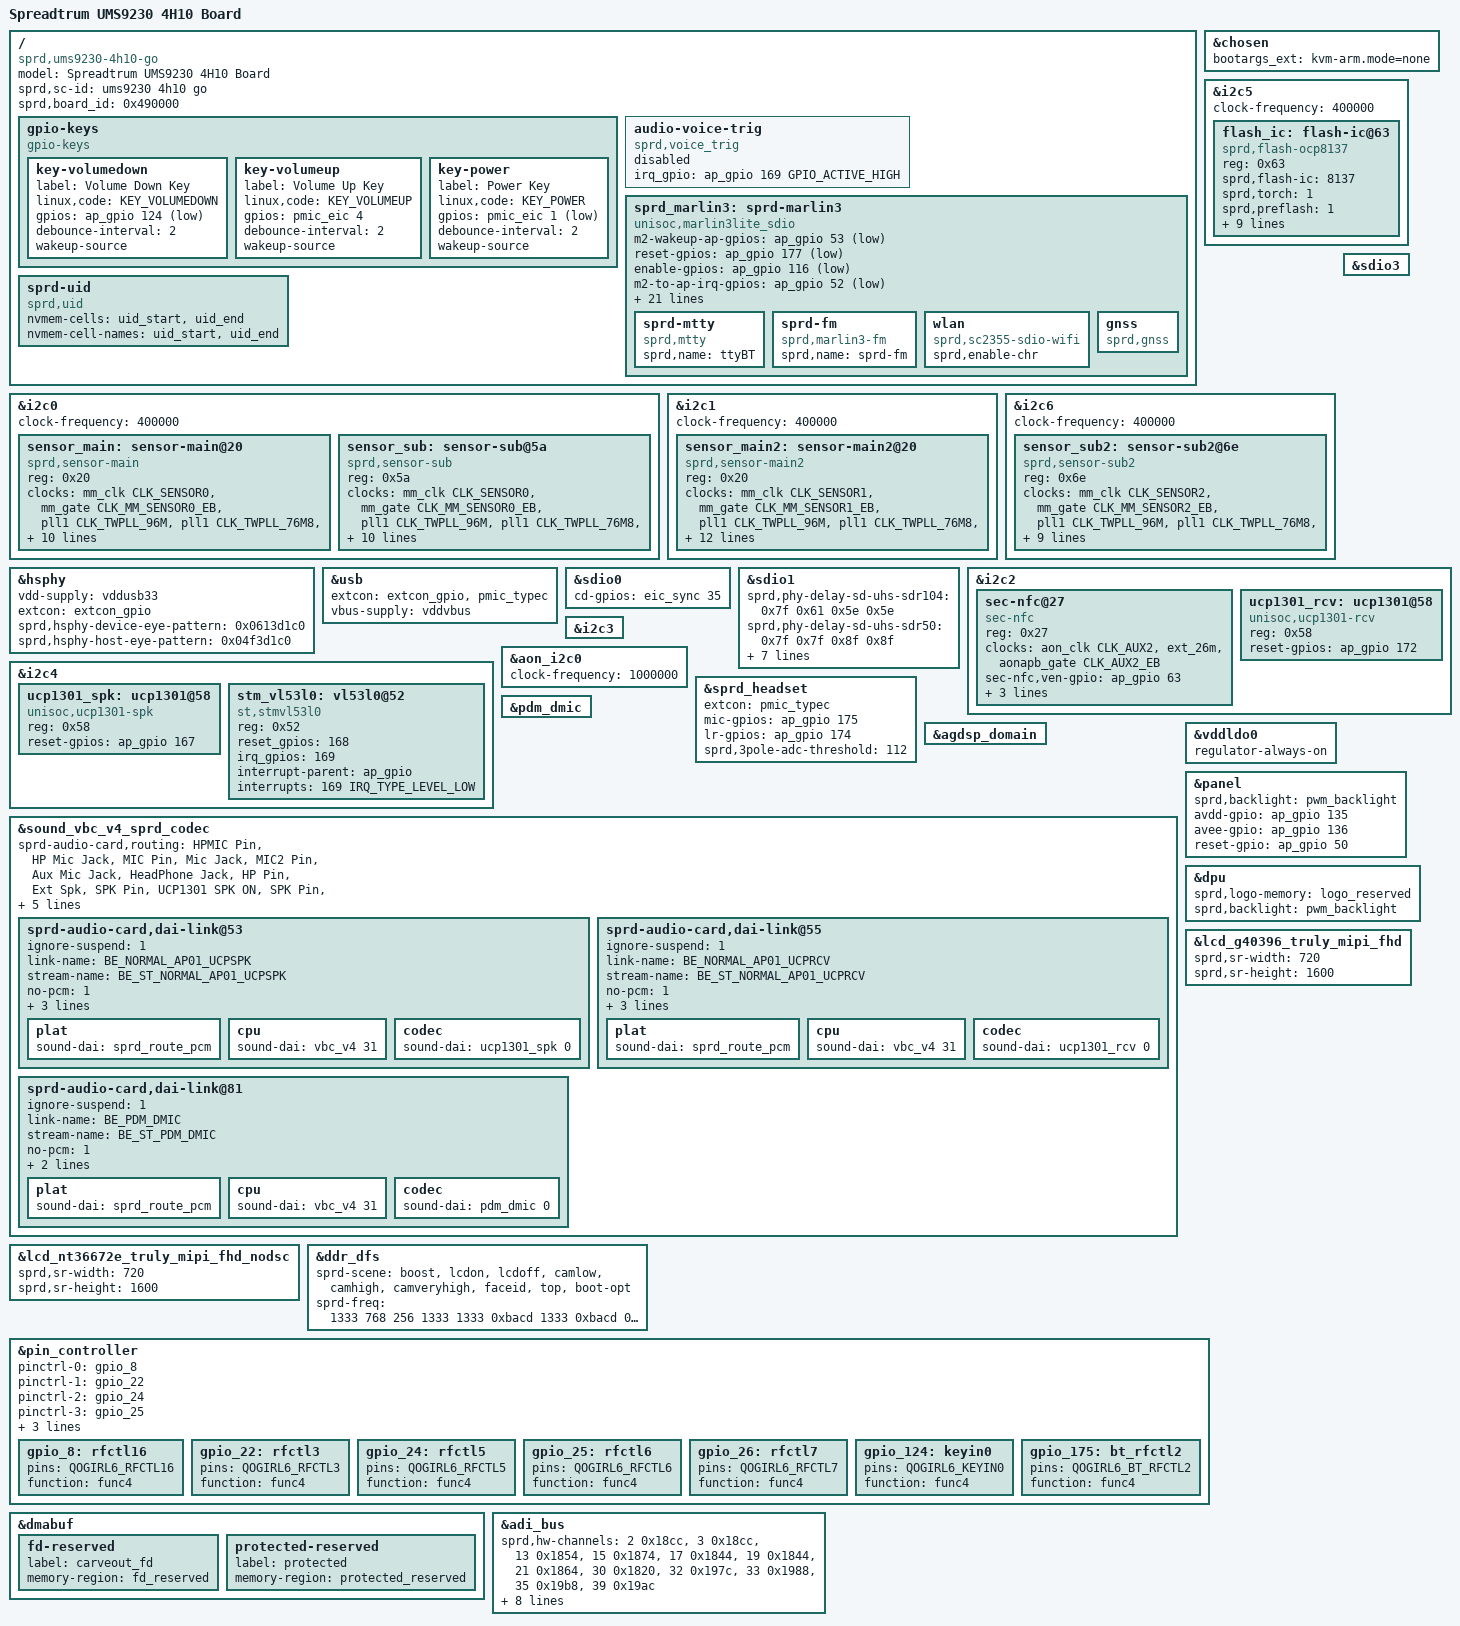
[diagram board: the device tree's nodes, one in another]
// SPDX-License-Identifier: GPL-2.0-only
/*
 * Spreadtrum Qogirn6lite board common DTS file
 *
 * Copyright (C) 2021, Unisoc Inc.
 */

/dts-v1/;
/plugin/;
#include <dt-bindings/input/input.h>
#include <dt-bindings/gpio/gpio.h>
#include <dt-bindings/interrupt-controller/arm-gic.h>
#include <dt-bindings/clock/sprd,ums9230-clk.h>
#include <dt-bindings/mfd/sprd,sc2730-regs.h>
#include <dt-bindings/mfd/sprd,sc2730-mask.h>
#include <dt-bindings/usb/pd.h>
#include "lcd/lcd_g40396_truly_mipi_fhd.dtsi"
#include "lcd/lcd_nt36672e_truly_mipi_fhd_nodsc.dtsi"
//#include "lcd/lcd_nt36672e_truly_mipi_fhd.dtsi"
#include "lcd/lcd_ft8725_boe_mipi_fhd_nodsc.dtsi"
#include "lcd/lcd_dummy_mipi.dtsi"
#include "touchscreen/ums9230-spi3-gpio144-145-tp.dtsi"
#include "reserved-memory/ums9230-4h10-go-overlay.dtsi"
#include "battery/ums9230-4h10-go-overlay.dtsi"
#include "wcn/wcn_modules.h"
#include "wcn/interface/wcn-sdio-register.dtsi"
#include "wcn/chip/wcn-marlin3lite-umw2652-register.dtsi"

/ {

	model = "Spreadtrum UMS9230 4H10 Board";

	compatible = "sprd,ums9230-4h10-go";

	sprd,sc-id = "ums9230 4h10 go";

	sprd,board_id = <0x490000>; //XXYY00:base board,XXYY00~XXYYFF:customize board

	fragment {
		target-path = "/";
		__overlay__ {
			/*fingerprint@0 {
				compatible = "microarray,afs121";
				fpint-gpios = <&eic_async 29 0>;
			};*/

			gpio-keys {
				compatible = "gpio-keys";

				key-volumedown {
					label = "Volume Down Key";
					linux,code = <KEY_VOLUMEDOWN>;
					gpios = <&ap_gpio 124 GPIO_ACTIVE_LOW>;
					debounce-interval = <2>;
					wakeup-source;
				};

				key-volumeup {
					label = "Volume Up Key";
					linux,code = <KEY_VOLUMEUP>;
					gpios = <&pmic_eic 4 GPIO_ACTIVE_HIGH>;
					debounce-interval = <2>;
					wakeup-source;
				};

				key-power {
					label = "Power Key";
					linux,code = <KEY_POWER>;
					gpios = <&pmic_eic 1 GPIO_ACTIVE_LOW>;
					debounce-interval = <2>;
					wakeup-source;
				};
			};

			audio-voice-trig {
				status = "disable";
				compatible = "sprd,voice_trig";
				irq_gpio = <&ap_gpio 169 GPIO_ACTIVE_HIGH>;
			};

			sprd_marlin3: sprd-marlin3 {
				compatible = "unisoc,marlin3lite_sdio";
				m2-wakeup-ap-gpios = <&ap_gpio 53 GPIO_ACTIVE_LOW>;
				reset-gpios = <&ap_gpio 177 GPIO_ACTIVE_LOW>;
				enable-gpios = <&ap_gpio 116 GPIO_ACTIVE_LOW>;
				m2-to-ap-irq-gpios = <&ap_gpio 52 GPIO_ACTIVE_LOW>;
				avdd12-supply = <&vddwcn>;
				avdd33-supply = <&vddwifipa>;
				dcxo18-supply = <&vddsim2>;
				vddwcn-parent-supply = <&vddgen1_slp>;
				clock-names = "clk_32k","source","enable";
				clocks = <&aon_clk CLK_AUX2>,
					 <&ext_32k>,
					 <&aonapb_gate CLK_AUX2_EB>;

				memory-region = <&wcn_reserved>;

				extcon = <&sdio1>;
				sdhci-name = <&sdio1>;
				sprd,btwf-file-name = "/dev/block/by-name/wcnmodem";
				sprd,gnss-file-name = "/vendor/firmware/gnssmodem.bin";
				adma-tx;
				adma-rx;

				/*
				 * bound parameter:
				 * [0]:addr offset, [1]:mask, [2]:unboundval, [3]:boundval
				 */
				avdd12-parent-bound-chip = <REG_ANA_SLP_DCDC_PD_CTRL MASK_ANA_SLP_DCDCGEN1_PD_EN 0x0 MASK_ANA_SLP_DCDCGEN1_PD_EN>;
				avdd12-bound-wbreq = <REG_ANA_LDO_XTL_EN10 MASK_ANA_LDO_VDDWCN_EXT_XTL3_EN 0x0 MASK_ANA_LDO_VDDWCN_EXT_XTL3_EN>;
				avdd33-bound-wbreq = <REG_ANA_LDO_XTL_EN11 MASK_ANA_LDO_VDDWIFIPA_EXT_XTL3_EN 0x0 MASK_ANA_LDO_VDDWIFIPA_EXT_XTL3_EN>;

				sprd-mtty {
					compatible = "sprd,mtty";
					sprd,name = "ttyBT";
				};

				sprd-fm {
					compatible = "sprd,marlin3-fm";
					sprd,name = "sprd-fm";
				};

				wlan {
					compatible = "sprd,sc2355-sdio-wifi";
					sprd,enable-chr;
				};

				gnss {
					compatible = "sprd,gnss";
				};
			};

			sprd-uid {
				compatible = "sprd,uid";
				nvmem-cells = <&uid_start>, <&uid_end>;
				nvmem-cell-names = "uid_start", "uid_end";
			};
		};
	};
};

&chosen {
	bootargs_ext = "kvm-arm.mode=none";
};

&i2c0 {
	status = "okay";
	clock-frequency = <400000>;
	#address-cells = <1>;
	#size-cells = <0>;

	sensor_main: sensor-main@20 {
		compatible = "sprd,sensor-main";
		reg = <0x20>;
		clock-names = "clk_src","sensor_eb",
			"clk_96m","clk_76m8",
			"clk_48m","clk_26m";
		clocks = <&mm_clk CLK_SENSOR0>,<&mm_gate CLK_MM_SENSOR0_EB>,
				<&pll1 CLK_TWPLL_96M>,<&pll1 CLK_TWPLL_76M8>,
				<&pll1 CLK_TWPLL_48M>,<&ext_26m>;
		vddio-supply = <&vddcamio>;
		vddcama-supply = <&vddcama0>;
		dvdd-gpios = <&ap_gpio 137 0>;
		vddcammot-supply = <&vddcammot>;
		reset-gpios = <&ap_gpio 45 0>;
		power-down-gpios = <&ap_gpio 47 0>;
		sprd,phyid = <0>;
		csi = <&csi0>;
		power-domains = <&mm_domain>;
	};

	sensor_sub: sensor-sub@5a {
		compatible = "sprd,sensor-sub";
		reg = <0x5a>;
		clock-names = "clk_src","sensor_eb",
			"clk_96m","clk_76m8",
			"clk_48m","clk_26m";
		clocks = <&mm_clk CLK_SENSOR0>,<&mm_gate CLK_MM_SENSOR0_EB>,
				<&pll1 CLK_TWPLL_96M>,<&pll1 CLK_TWPLL_76M8>,
				<&pll1 CLK_TWPLL_48M>,<&ext_26m>;
		vddio-supply = <&vddcamio>;
		vddcama-supply = <&vddcama0>;
		dvdd-gpios = <&ap_gpio 137 0>;
		vddcammot-supply = <&vddcammot>;
		reset-gpios = <&ap_gpio 44 0>;
		power-down-gpios = <&ap_gpio 46 0>;
	/*	mipi-switch-en-gpios = <&ap_gpio 55 0>;*/
	/*	mipi-switch-mode-gpios = <&ap_gpio 8 0>;*/
		sprd,phyid = <2>;
		csi = <&csi0>;
		power-domains = <&mm_domain>;
	};
};

&i2c1 {
	status = "okay";
	clock-frequency = <400000>;
	#address-cells = <1>;
	#size-cells = <0>;

	sensor_main2: sensor-main2@20 {
		compatible = "sprd,sensor-main2";
		reg = <0x20>;
		clock-names = "clk_src","sensor_eb",
			"clk_96m","clk_76m8",
			"clk_48m","clk_26m";
		clocks = <&mm_clk CLK_SENSOR1>,<&mm_gate CLK_MM_SENSOR1_EB>,
				<&pll1 CLK_TWPLL_96M>,<&pll1 CLK_TWPLL_76M8>,
				<&pll1 CLK_TWPLL_48M>,<&ext_26m>;
		vddio-supply = <&vddcamio>;
		vddcama-supply = <&vddcama1>;
		vddcamd-supply = <&vddcamd0>;
		vddcammot-supply = <&vddcammot>;
		avdd-gpios = <&ap_gpio 10 0>;
		mot-gpios = <&ap_gpio 88 0>;
		reset-gpios = <&ap_gpio 41 0>;
		power-down-gpios = <&ap_gpio 40 0>;
	/*	mipi-switch-en-gpios = <&ap_gpio 55 0>;*/
	/*	mipi-switch-mode-gpios = <&ap_gpio 8 0>;*/
		sprd,phyid = <4>;
		csi = <&csi1>;
		power-domains = <&mm_domain>;
	};


};

&i2c5 {
	status = "okay";
	clock-frequency = <400000>;
	#address-cells = <1>;
	#size-cells = <0>;

	flash_ic: flash-ic@63 {
		compatible = "sprd,flash-ocp8137";
		reg = <0x63>;
		sprd,flash-ic = <8137>;
		sprd,torch = <1>;
		sprd,preflash = <1>;
		sprd,highlight = <1>;
		sprd,torch-level = <128>;
		sprd,preflash-level = <128>;
		sprd,highlight-level = <128>;
		sprd,lvfm-enable = <1>;
		flash-torch-en-gpios = <&ap_gpio 32 0>;
		flash-chip-en-gpios = <&ap_gpio 138 0>;
		flash-en-gpios = <&ap_gpio 139 0>;
		flash-sync-gpios = <&ap_gpio 121 0>;
	};
};

&i2c6 {
	status = "okay";
	clock-frequency = <400000>;
	#address-cells = <1>;
	#size-cells = <0>;

	sensor_sub2: sensor-sub2@6e {
		compatible = "sprd,sensor-sub2";
		reg = <0x6e>;
		clock-names = "clk_src","sensor_eb",
			"clk_96m","clk_76m8",
			"clk_48m","clk_26m";
		clocks = <&mm_clk CLK_SENSOR2>,<&mm_gate CLK_MM_SENSOR2_EB>,
			<&pll1 CLK_TWPLL_96M>,<&pll1 CLK_TWPLL_76M8>,
			<&pll1 CLK_TWPLL_48M>,<&ext_26m>;
		vddio-supply = <&vddcamio>;
		avdd-gpios = <&ap_gpio 130 0>;
		vddcamd-supply = <&vddcamd1>;
		vddcammot-supply = <&vddcammot>;
		mot-gpios = <&ap_gpio 112 0>;
		reset-gpios = <&ap_gpio 114 0>;
	/*	power-down-gpios = <&ap_gpio 40 0>;*/
		sprd,phyid = <3>;
		csi = <&csi2>;
	};
};

&hsphy {
	vdd-supply = <&vddusb33>;
	extcon = <&extcon_gpio>;
	sprd,hsphy-device-eye-pattern = <0x0613d1c0>;
	sprd,hsphy-host-eye-pattern = <0x04f3d1c0>;
	status = "okay";
};

&usb {
	extcon = <&extcon_gpio>, <&pmic_typec>;
	vbus-supply = <&vddvbus>;
	status = "okay";
};

&sdio0 {
	cd-gpios = <&eic_sync 35 GPIO_ACTIVE_HIGH>;
};

&sdio1 {
	sprd,phy-delay-sd-uhs-sdr104 = <0x7f 0x61 0x5e 0x5e>;
	sprd,phy-delay-sd-uhs-sdr50 = <0x7f 0x7f 0x8f 0x8f>;
	sd-uhs-sdr104;
	sd-uhs-sdr50;
	bus-width = <4>;
	sprd,name = "sdio_wifi";
	sprd,sdio-adma;
	no-sd;
	no-mmc;
	status = "okay";
};

&sdio3 {
	status = "okay";
};

&i2c2 {
	status = "okay";
	#address-cells = <1>;
	#size-cells = <0>;
	sec-nfc@27 {
		compatible = "sec-nfc";
		reg = <0x27>;
		clock-names = "nfc_clk","source","enable";
		clocks = <&aon_clk CLK_AUX2>, <&ext_26m>, <&aonapb_gate CLK_AUX2_EB>;
		sec-nfc,ven-gpio = <&ap_gpio 63 0>;
		sec-nfc,firm-gpio = <&ap_gpio 61 0>;
		sec-nfc,irq-gpio = <&ap_gpio 62 0>;
		sec-nfc,clk-req = <&ap_gpio 60 0>;
	};

	ucp1301_rcv: ucp1301@58 {
		compatible = "unisoc,ucp1301-rcv";
		reg = <0x58>;
		reset-gpios = <&ap_gpio 172 GPIO_ACTIVE_HIGH>;
		#sound-dai-cells = <1>;
	};
};

&i2c3 {
	status = "okay";
	#address-cells = <1>;
	#size-cells = <0>;
};

&i2c4 {
	status = "okay";
	#address-cells = <1>;
	#size-cells = <0>;
	ucp1301_spk: ucp1301@58 {
		compatible = "unisoc,ucp1301-spk";
		reg = <0x58>;
		reset-gpios = <&ap_gpio 167 GPIO_ACTIVE_HIGH>;
		#sound-dai-cells = <1>;
	};

	stm_vl53l0: vl53l0@52 {
		compatible = "st,stmvl53l0";
		reg = <0x52>;
		reset_gpios = <168>;
		irq_gpios = <169>;
		interrupt-parent = <&ap_gpio>;
		interrupts = <169 IRQ_TYPE_LEVEL_LOW>;
	};
};

&aon_i2c0 {
	status = "okay";
	clock-frequency = <1000000>;
};

&sprd_headset {
	status = "okay";
	extcon = <&pmic_typec>;
	mic-gpios = <&ap_gpio 175 GPIO_ACTIVE_HIGH>;
	lr-gpios = <&ap_gpio 174 GPIO_ACTIVE_HIGH>;
	sprd,3pole-adc-threshold = <112>;
};

&pdm_dmic {
	status = "okay";
};

&agdsp_domain {
	status = "okay";
};

&sound_vbc_v4_sprd_codec {
	status = "okay";
	sprd-audio-card,routing =
		"HPMIC Pin", "HP Mic Jack",
		"MIC Pin", "Mic Jack",
		"MIC2 Pin", "Aux Mic Jack",
		"HeadPhone Jack", "HP Pin",
		"Ext Spk", "SPK Pin",
		"UCP1301 SPK ON", "SPK Pin",
		"Ext Spk", "UCP1301 SPK",
		"PDM DMIC2 ON", "SPK Pin",
		"Ext Spk", "PDM_DMIC2",
		"DMIC Pin", "DMic Jack",
		"DMIC1 Pin", "DMic1 Jack",
		"Ext Ear", "EAR Pin",
		"UCP1301 RCV ON", "EAR Pin",
		"Ext Ear", "UCP1301 RCV";

	/* 35: ucp1301 normal ap01 */
	sprd-audio-card,dai-link@53 {
		ignore-suspend = <1>;
		link-name = "BE_NORMAL_AP01_UCPSPK";
		stream-name = "BE_ST_NORMAL_AP01_UCPSPK";
		no-pcm = <1>;
		dpcm-playback = <1>;
		be-id = <0>;
		dai-format = "i2s";
		plat {
			sound-dai = <&sprd_route_pcm>;
		};
		cpu {
			sound-dai = <&vbc_v4 31>;
		};
		codec {
			sound-dai = <&ucp1301_spk 0>;
		};
	};

	/*
	 * node 54 and node 55 (index 36 and 37) are reserved for
	 * "ucp1301-spk2" and "ucp1301-rcv"
	 * nodes from 56 to 67 (index from 38 to 49) are used by HIFI
	 */
	/* 37: ucp1301 normal ap01 rcv */
	sprd-audio-card,dai-link@55 {
		ignore-suspend = <1>;
		link-name = "BE_NORMAL_AP01_UCPRCV";
		stream-name = "BE_ST_NORMAL_AP01_UCPRCV";
		no-pcm = <1>;
		dpcm-playback = <1>;
		be-id = <0>;
		dai-format = "i2s";
		plat {
			sound-dai = <&sprd_route_pcm>;
		};
		cpu {
			sound-dai = <&vbc_v4 31>;
		};
		codec {
			sound-dai = <&ucp1301_rcv 0>;
		};
	};

	/* 63: pdm dmic */
	sprd-audio-card,dai-link@81 {
		ignore-suspend = <1>;
		link-name = "BE_PDM_DMIC";
		stream-name = "BE_ST_PDM_DMIC";
		no-pcm = <1>;
		dpcm-capture = <1>;
		be-id = <0>;
		//dai-format = "i2s";
		plat {
			sound-dai = <&sprd_route_pcm>;
		};
		cpu {
			sound-dai = <&vbc_v4 31>;
		};
		codec {
			sound-dai = <&pdm_dmic 0>;
		};
	};
};

&vddldo0 {
	regulator-always-on;
};

&panel {
	sprd,backlight = <&pwm_backlight>;
	avdd-gpio = <&ap_gpio 135 GPIO_ACTIVE_HIGH>;
	avee-gpio = <&ap_gpio 136 GPIO_ACTIVE_HIGH>;
	reset-gpio = <&ap_gpio 50 GPIO_ACTIVE_HIGH>;
};

&dpu {
	sprd,logo-memory = <&logo_reserved>;

	sprd,backlight = <&pwm_backlight>;
};

&lcd_g40396_truly_mipi_fhd {
	sprd,sr-width = <720>;
	sprd,sr-height = <1600>;
};

&lcd_nt36672e_truly_mipi_fhd_nodsc {
	sprd,sr-width = <720>;
	sprd,sr-height = <1600>;
};

&ddr_dfs {
	  sprd-scene = "boost", "lcdon", "lcdoff", "camlow",
			"camhigh", "camveryhigh", "faceid", "top", "boot-opt";
	  sprd-freq = <1333 768 256 1333 1333 0xbacd 1333 0xbacd 0xbacd>;
};

&pin_controller {
	pinctrl-names =
	/* rfctl16 ,rfctl3, rfctl5 */
	"gpio_8", "gpio_22", "gpio_24",
	/* rfctl6, rfctl7, keyin0 */
	"gpio_25", "gpio_26", "gpio_124",
	/* bt_rfctl2 */
	"gpio_175";
	pinctrl-0 = <&gpio_8>;
	pinctrl-1 = <&gpio_22>;
	pinctrl-2 = <&gpio_24>;
	pinctrl-3 = <&gpio_25>;
	pinctrl-4 = <&gpio_26>;
	pinctrl-5 = <&gpio_124>;
	pinctrl-6 = <&gpio_175>;

	gpio_8: rfctl16 {
		pins = "QOGIRL6_RFCTL16";
		function = "func4";
	};

	gpio_22: rfctl3 {
		pins = "QOGIRL6_RFCTL3";
		function = "func4";
	};

	gpio_24: rfctl5 {
		pins = "QOGIRL6_RFCTL5";
		function = "func4";
	};

	gpio_25: rfctl6 {
		pins = "QOGIRL6_RFCTL6";
		function = "func4";
	};

	gpio_26: rfctl7 {
		pins = "QOGIRL6_RFCTL7";
		function = "func4";
	};

	gpio_124: keyin0 {
		pins = "QOGIRL6_KEYIN0";
		function = "func4";
	};

	gpio_175: bt_rfctl2 {
		pins = "QOGIRL6_BT_RFCTL2";
		function = "func4";
	};
};

&dmabuf {
	fd-reserved {
		label = "carveout_fd";
		memory-region = <&fd_reserved>;
	};

	protected-reserved {
		label = "protected";
		memory-region = <&protected_reserved>;
	};
};

&adi_bus {
	sprd,hw-channels = <2 0x18cc>, <3 0x18cc>, <13 0x1854>, <15 0x1874>,
			<17 0x1844>, <19 0x1844>, <21 0x1864>, <30 0x1820>,
			<32 0x197c>, <33 0x1988>, <35 0x19b8>, <39 0x19ac>;
	sprd,hw-channels0 = <2 0x18cc>, <3 0x18cc>, <13 0x1874>, <15 0x1874>,
			<17 0x1844>, <19 0x1854>, <21 0x1864>, <30 0x1820>,
			<32 0x197c>, <33 0x1988>, <35 0x19b8>, <39 0x19ac>;
	sprd,hw-channels1 = <2 0x18cc>, <3 0x18cc>, <13 0x1854>, <15 0x1874>,
			<17 0x1844>, <19 0x1844>, <21 0x1864>, <30 0x1820>,
			<32 0x197c>, <33 0x1988>, <35 0x19b8>, <39 0x19ac>;
};
